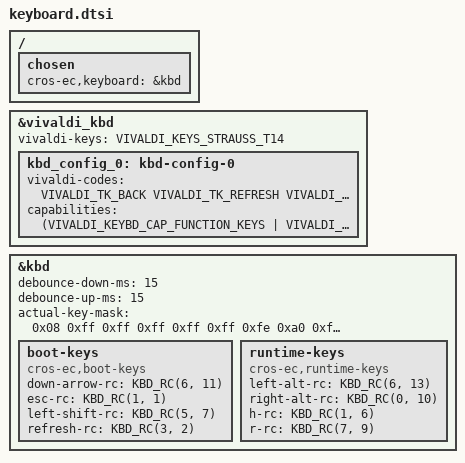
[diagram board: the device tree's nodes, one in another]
/* Copyright 2024 The ChromiumOS Authors
 * Use of this source code is governed by a BSD-style license that can be
 * found in the LICENSE file.
 */

/ {
	chosen {
		cros-ec,keyboard = &kbd;
	};
};

&vivaldi_kbd {
	vivaldi-keys = <VIVALDI_KEYS_STRAUSS_T14>;

	kbd_config_0: kbd-config-0 {
		vivaldi-codes = <
			VIVALDI_TK_BACK               /* T1 */
			VIVALDI_TK_REFRESH            /* T2 */
			VIVALDI_TK_FULLSCREEN         /* T3 */
			VIVALDI_TK_OVERVIEW           /* T4 */
			VIVALDI_TK_SNAPSHOT           /* T5 */
			VIVALDI_TK_BRIGHTNESS_DOWN    /* T6 */
			VIVALDI_TK_BRIGHTNESS_UP      /* T7 */
			VIVALDI_TK_DICTATE            /* T8 */
			VIVALDI_TK_ACCESSIBILITY      /* T9 */
			VIVALDI_TK_PLAY_PAUSE         /* T10 */
			VIVALDI_TK_MICMUTE            /* T11 */
			VIVALDI_TK_VOL_MUTE           /* T12 */
			VIVALDI_TK_VOL_DOWN           /* T13 */
			VIVALDI_TK_VOL_UP             /* T14 */
		>;
		capabilities = <
			(VIVALDI_KEYBD_CAP_FUNCTION_KEYS |
			 VIVALDI_KEYBD_CAP_ASSISTANT_KEY)
		>;
       };
};

&kbd {
	debounce-down-ms = <15>;
	debounce-up-ms = <15>;
	actual-key-mask = <
		0x08 /* C0 */
		0xff /* C1 */
		0xff /* C2 */
		0xff /* C3 */
		0xff /* C4 */
		0xff /* C5 */
		0xfe /* C6 */
		0xa0 /* C7 */
		0xff /* C8 */
		0xf6 /* C9 */
		0x01 /* C10 */
		0xff /* C11 */
		0xc0 /* C12 */
		0x40 /* C13 */
		0x0a /* C14 */
		0x40 /* C15 */
		0x01 /* C16 */
		0xff /* C17 */
	>;

	boot-keys {
		compatible = "cros-ec,boot-keys";
		down-arrow-rc = <KBD_RC(6, 11)>;
		esc-rc = <KBD_RC(1, 1)>;
		left-shift-rc = <KBD_RC(5, 7)>;
		refresh-rc = <KBD_RC(3, 2)>;
	};

	runtime-keys {
		compatible = "cros-ec,runtime-keys";
		left-alt-rc = <KBD_RC(6, 13)>;
		right-alt-rc = <KBD_RC(0, 10)>;
		h-rc = <KBD_RC(1, 6)>;
		r-rc = <KBD_RC(7, 9)>;
	};
};
